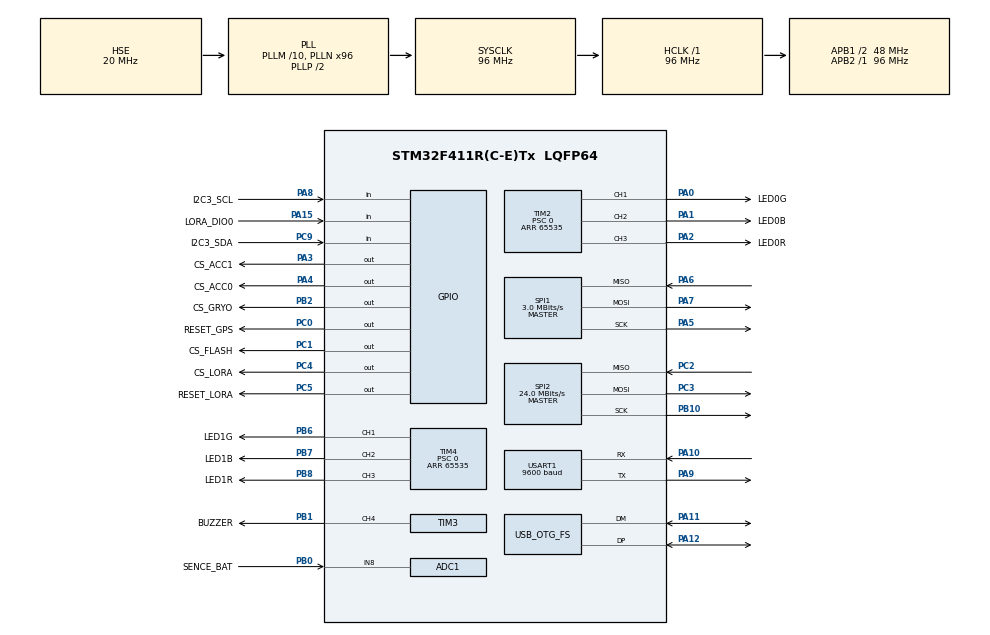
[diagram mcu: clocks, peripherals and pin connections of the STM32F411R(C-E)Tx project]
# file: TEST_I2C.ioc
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ADC1.Channel-0\#ChannelRegularConversion=ADC_CHANNEL_8
ADC1.NbrOfConversionFlag=1
ADC1.Rank-0\#ChannelRegularConversion=1
ADC1.SamplingTime-0\#ChannelRegularConversion=ADC_SAMPLETIME_3CYCLES
ADC1.master=1
Dma.ADC1.6.Direction=DMA_PERIPH_TO_MEMORY
Dma.ADC1.6.FIFOMode=DMA_FIFOMODE_DISABLE
Dma.ADC1.6.Instance=DMA2_Stream4
Dma.ADC1.6.MemDataAlignment=DMA_MDATAALIGN_HALFWORD
Dma.ADC1.6.MemInc=DMA_MINC_ENABLE
Dma.ADC1.6.Mode=DMA_NORMAL
Dma.ADC1.6.PeriphDataAlignment=DMA_PDATAALIGN_HALFWORD
Dma.ADC1.6.PeriphInc=DMA_PINC_DISABLE
Dma.ADC1.6.Priority=DMA_PRIORITY_LOW
Dma.Request0=SPI1_RX
Dma.Request1=SPI1_TX
Dma.Request2=SPI2_RX
Dma.Request3=SPI2_TX
Dma.Request4=USART1_RX
Dma.Request5=USART1_TX
Dma.Request6=ADC1
Dma.SPI1_RX.0.Direction=DMA_PERIPH_TO_MEMORY
Dma.SPI1_RX.0.FIFOMode=DMA_FIFOMODE_DISABLE
Dma.SPI1_RX.0.Instance=DMA2_Stream0
Dma.SPI1_RX.0.MemDataAlignment=DMA_MDATAALIGN_BYTE
Dma.SPI1_RX.0.MemInc=DMA_MINC_ENABLE
Dma.SPI1_RX.0.Mode=DMA_NORMAL
Dma.SPI1_RX.0.PeriphDataAlignment=DMA_PDATAALIGN_BYTE
Dma.SPI1_RX.0.PeriphInc=DMA_PINC_DISABLE
Dma.SPI1_RX.0.Priority=DMA_PRIORITY_LOW
Dma.SPI1_TX.1.Direction=DMA_MEMORY_TO_PERIPH
Dma.SPI1_TX.1.FIFOMode=DMA_FIFOMODE_DISABLE
Dma.SPI1_TX.1.Instance=DMA2_Stream2
Dma.SPI1_TX.1.MemDataAlignment=DMA_MDATAALIGN_BYTE
Dma.SPI1_TX.1.MemInc=DMA_MINC_ENABLE
Dma.SPI1_TX.1.Mode=DMA_NORMAL
Dma.SPI1_TX.1.PeriphDataAlignment=DMA_PDATAALIGN_BYTE
Dma.SPI1_TX.1.PeriphInc=DMA_PINC_DISABLE
Dma.SPI1_TX.1.Priority=DMA_PRIORITY_LOW
Dma.SPI2_RX.2.Direction=DMA_PERIPH_TO_MEMORY
Dma.SPI2_RX.2.FIFOMode=DMA_FIFOMODE_DISABLE
Dma.SPI2_RX.2.Instance=DMA1_Stream3
Dma.SPI2_RX.2.MemDataAlignment=DMA_MDATAALIGN_BYTE
Dma.SPI2_RX.2.MemInc=DMA_MINC_ENABLE
Dma.SPI2_RX.2.Mode=DMA_NORMAL
Dma.SPI2_RX.2.PeriphDataAlignment=DMA_PDATAALIGN_BYTE
Dma.SPI2_RX.2.PeriphInc=DMA_PINC_DISABLE
Dma.SPI2_RX.2.Priority=DMA_PRIORITY_LOW
Dma.SPI2_TX.3.Direction=DMA_MEMORY_TO_PERIPH
Dma.SPI2_TX.3.FIFOMode=DMA_FIFOMODE_DISABLE
Dma.SPI2_TX.3.Instance=DMA1_Stream4
Dma.SPI2_TX.3.MemDataAlignment=DMA_MDATAALIGN_BYTE
Dma.SPI2_TX.3.MemInc=DMA_MINC_ENABLE
Dma.SPI2_TX.3.Mode=DMA_NORMAL
Dma.SPI2_TX.3.PeriphDataAlignment=DMA_PDATAALIGN_BYTE
Dma.SPI2_TX.3.PeriphInc=DMA_PINC_DISABLE
Dma.SPI2_TX.3.Priority=DMA_PRIORITY_LOW
Dma.USART1_RX.4.Direction=DMA_PERIPH_TO_MEMORY
Dma.USART1_RX.4.FIFOMode=DMA_FIFOMODE_DISABLE
Dma.USART1_RX.4.Instance=DMA2_Stream5
Dma.USART1_RX.4.MemDataAlignment=DMA_MDATAALIGN_BYTE
Dma.USART1_RX.4.MemInc=DMA_MINC_ENABLE
Dma.USART1_RX.4.Mode=DMA_NORMAL
Dma.USART1_RX.4.PeriphDataAlignment=DMA_PDATAALIGN_BYTE
Dma.USART1_RX.4.PeriphInc=DMA_PINC_DISABLE
Dma.USART1_RX.4.Priority=DMA_PRIORITY_LOW
Dma.USART1_TX.5.Direction=DMA_MEMORY_TO_PERIPH
Dma.USART1_TX.5.FIFOMode=DMA_FIFOMODE_DISABLE
Dma.USART1_TX.5.Instance=DMA2_Stream7
Dma.USART1_TX.5.MemDataAlignment=DMA_MDATAALIGN_BYTE
Dma.USART1_TX.5.MemInc=DMA_MINC_ENABLE
Dma.USART1_TX.5.Mode=DMA_NORMAL
Dma.USART1_TX.5.PeriphDataAlignment=DMA_PDATAALIGN_BYTE
Dma.USART1_TX.5.PeriphInc=DMA_PINC_DISABLE
Dma.USART1_TX.5.Priority=DMA_PRIORITY_LOW
Mcu.Family=STM32F4
Mcu.Name=STM32F411R(C-E)Tx
Mcu.Package=LQFP64
NVIC.DMA1_Stream3_IRQn=true\:0\:0\:false\:false\:true\:false\:true\:true
NVIC.DMA1_Stream4_IRQn=true\:0\:0\:false\:false\:true\:false\:true\:true
NVIC.DMA2_Stream0_IRQn=true\:0\:0\:false\:false\:true\:false\:true\:true
NVIC.DMA2_Stream2_IRQn=true\:0\:0\:false\:false\:true\:false\:true\:true
NVIC.DMA2_Stream4_IRQn=true\:0\:0\:false\:false\:true\:false\:true\:true
NVIC.DMA2_Stream5_IRQn=true\:0\:0\:false\:false\:true\:false\:true\:true
NVIC.DMA2_Stream7_IRQn=true\:0\:0\:false\:false\:true\:false\:true\:true
NVIC.OTG_FS_IRQn=true\:0\:0\:false\:false\:true\:false\:true\:true
NVIC.PriorityGroup=NVIC_PRIORITYGROUP_4
PA0-WKUP.GPIO_Label=LED0G
PA0-WKUP.Signal=S_TIM2_CH1_ETR
PA1.GPIO_Label=LED0B
PA1.Signal=S_TIM2_CH2
PA10.Mode=Asynchronous
PA10.Signal=USART1_RX
PA11.Mode=Device_Only
PA11.Signal=USB_OTG_FS_DM
PA12.Mode=Device_Only
PA12.Signal=USB_OTG_FS_DP
PA13.Mode=Serial_Wire
PA13.Signal=SYS_JTMS-SWDIO
PA14.Mode=Serial_Wire
PA14.Signal=SYS_JTCK-SWCLK
PA15.GPIO_Label=LORA_DIO0
PA15.Signal=GPIO_Input
PA2.GPIO_Label=LED0R
PA2.Signal=S_TIM2_CH3
PA3.GPIO_Label=CS_ACC1
PA3.PinState=GPIO_PIN_SET
PA3.Signal=GPIO_Output
PA4.GPIO_Label=CS_ACC0
PA4.PinState=GPIO_PIN_SET
PA4.Signal=GPIO_Output
PA5.Mode=Full_Duplex_Master
PA5.Signal=SPI1_SCK
PA6.Mode=Full_Duplex_Master
PA6.Signal=SPI1_MISO
PA7.Mode=Full_Duplex_Master
PA7.Signal=SPI1_MOSI
PA8.GPIO_Label=I2C3_SCL
PA8.Signal=GPIO_Input
PA9.Mode=Asynchronous
PA9.Signal=USART1_TX
PB0.GPIO_Label=SENCE_BAT
PB0.Signal=ADCx_IN8
PB1.GPIO_Label=BUZZER
PB1.Signal=S_TIM3_CH4
PB10.Mode=Full_Duplex_Master
PB10.Signal=SPI2_SCK
PB2.GPIO_Label=CS_GRYO
PB2.PinState=GPIO_PIN_SET
PB2.Signal=GPIO_Output
PB6.GPIO_Label=LED1G
PB6.Signal=S_TIM4_CH1
PB7.GPIO_Label=LED1B
PB7.Signal=S_TIM4_CH2
PB8.GPIO_Label=LED1R
PB8.Signal=S_TIM4_CH3
PC0.GPIO_Label=RESET_GPS
PC0.PinState=GPIO_PIN_SET
PC0.Signal=GPIO_Output
PC1.GPIO_Label=CS_FLASH
PC1.PinState=GPIO_PIN_SET
PC1.Signal=GPIO_Output
PC14-OSC32_IN.Mode=LSE-External-Oscillator
PC14-OSC32_IN.Signal=RCC_OSC32_IN
PC15-OSC32_OUT.Mode=LSE-External-Oscillator
PC15-OSC32_OUT.Signal=RCC_OSC32_OUT
PC2.Mode=Full_Duplex_Master
PC2.Signal=SPI2_MISO
PC3.Mode=Full_Duplex_Master
PC3.Signal=SPI2_MOSI
PC4.GPIO_Label=CS_LORA
PC4.PinState=GPIO_PIN_SET
PC4.Signal=GPIO_Output
PC5.GPIO_Label=RESET_LORA
PC5.PinState=GPIO_PIN_SET
PC5.Signal=GPIO_Output
PC9.GPIO_Label=I2C3_SDA
PC9.Signal=GPIO_Input
PH0\ -\ OSC_IN.Mode=HSE-External-Oscillator
PH0\ -\ OSC_IN.Signal=RCC_OSC_IN
PH1\ -\ OSC_OUT.Mode=HSE-External-Oscillator
PH1\ -\ OSC_OUT.Signal=RCC_OSC_OUT
ProjectManager.HeapSize=0x200
ProjectManager.StackSize=0x400
ProjectManager.TargetToolchain=CMake
RCC.48MHZClocksFreq_Value=48000000
RCC.AHBFreq_Value=96000000
RCC.APB1CLKDivider=RCC_HCLK_DIV2
RCC.APB1Freq_Value=48000000
RCC.APB1TimFreq_Value=96000000
RCC.APB2Freq_Value=96000000
RCC.APB2TimFreq_Value=96000000
RCC.CortexFreq_Value=96000000
RCC.HCLKFreq_Value=96000000
RCC.HSE_VALUE=20000000
RCC.HSI_VALUE=16000000
RCC.PLLM=10
RCC.PLLN=96
RCC.SYSCLKFreq_VALUE=96000000
RCC.SYSCLKSource=RCC_SYSCLKSOURCE_PLLCLK
RCC.VCOOutputFreq_Value=192000000
SH.ADCx_IN8.0=ADC1_IN8,IN8
SH.S_TIM2_CH1_ETR.0=TIM2_CH1,PWM Generation1 CH1
SH.S_TIM2_CH2.0=TIM2_CH2,PWM Generation2 CH2
SH.S_TIM2_CH3.0=TIM2_CH3,PWM Generation3 CH3
SH.S_TIM3_CH4.0=TIM3_CH4,PWM Generation4 CH4
SH.S_TIM4_CH1.0=TIM4_CH1,PWM Generation1 CH1
SH.S_TIM4_CH2.0=TIM4_CH2,PWM Generation2 CH2
SH.S_TIM4_CH3.0=TIM4_CH3,PWM Generation3 CH3
SPI1.BaudRatePrescaler=SPI_BAUDRATEPRESCALER_32
SPI1.CalculateBaudRate=3.0 MBits/s
SPI1.Direction=SPI_DIRECTION_2LINES
SPI1.Mode=SPI_MODE_MASTER
SPI1.VirtualType=VM_MASTER
SPI2.CalculateBaudRate=24.0 MBits/s
SPI2.Direction=SPI_DIRECTION_2LINES
SPI2.Mode=SPI_MODE_MASTER
SPI2.VirtualType=VM_MASTER
TIM2.Channel-PWM\ Generation1\ CH1=TIM_CHANNEL_1
TIM2.Channel-PWM\ Generation2\ CH2=TIM_CHANNEL_2
TIM2.Channel-PWM\ Generation3\ CH3=TIM_CHANNEL_3
TIM2.Period=65535
TIM2.Prescaler=0
TIM3.Channel-PWM\ Generation4\ CH4=TIM_CHANNEL_4
TIM3.Period=65535
TIM3.Prescaler=0
TIM4.Channel-PWM\ Generation1\ CH1=TIM_CHANNEL_1
TIM4.Channel-PWM\ Generation2\ CH2=TIM_CHANNEL_2
TIM4.Channel-PWM\ Generation3\ CH3=TIM_CHANNEL_3
TIM4.Period=65535
TIM4.Prescaler=0
USART1.BaudRate=9600
USART1.VirtualMode=VM_ASYNC
USB_DEVICE.CLASS_NAME_FS=CDC
USB_DEVICE.VirtualMode=Cdc
USB_DEVICE.VirtualModeFS=Cdc_FS
USB_OTG_FS.VirtualMode=Device_Only
VP_TIM2_VS_ClockSourceINT.Mode=Internal
VP_TIM3_VS_ClockSourceINT.Mode=Internal
VP_TIM4_VS_ClockSourceINT.Mode=Internal
VP_USB_DEVICE_VS_USB_DEVICE_CDC_FS.Mode=CDC_FS
board=custom

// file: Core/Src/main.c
/* USER CODE BEGIN Header */
/**
  ******************************************************************************
  * @file           : main.c
  * @brief          : Main program body
  ******************************************************************************
  * @attention
  *
  * Copyright (c) 2025 STMicroelectronics.
  * All rights reserved.
  *
  * This software is licensed under terms that can be found in the LICENSE file
  * in the root directory of this software component.
  * If no LICENSE file comes with this software, it is provided AS-IS.
  *
  ******************************************************************************
  */
/* USER CODE END Header */
#include "main.h"
#include "adc.h"
#include "dma.h"
#include "spi.h"
#include "tim.h"
#include "usart.h"
#include "usb_device.h"
#include "gpio.h"
#include "usbd_cdc_if.h"

void SystemClock_Config(void);

int main(void)
{

  /* MCU Configuration--------------------------------------------------------*/

  /* Reset of all peripherals, Initializes the Flash interface and the Systick. */
  HAL_Init();

  /* Configure the system clock */
  SystemClock_Config();

  /* Initialize all configured peripherals */
  MX_GPIO_Init();
  MX_DMA_Init();
  MX_SPI2_Init();
  MX_TIM2_Init();
  MX_TIM4_Init();
  MX_USART1_UART_Init();
  MX_ADC1_Init();
  MX_SPI1_Init();
  MX_TIM3_Init();
  MX_USB_DEVICE_Init();
  /* USER CODE BEGIN 2 */

  uint8_t sda, scl;

  char usb_buffer[64];

  /* USER CODE END 2 */

  /* Infinite loop */
  /* USER CODE BEGIN WHILE */
  while (1)
  {

    HAL_GPIO_ReadPin(I2C3_SDA_GPIO_Port, I2C3_SDA_Pin) ? (sda = 1) : (sda = 0);
    HAL_GPIO_ReadPin(I2C3_SCL_GPIO_Port, I2C3_SCL_Pin) ? (scl = 1) : (scl = 0);

    sprintf(usb_buffer, "SDA: %d, SCL: %d\r\n", sda, scl);
    CDC_Transmit_FS((uint8_t *)usb_buffer, strlen(usb_buffer));

  HAL_Delay(1000); // Transmit every second
    /* USER CODE END WHILE */

  }
}

void SystemClock_Config(void)
{
  RCC_OscInitTypeDef RCC_OscInitStruct = {0};
  RCC_ClkInitTypeDef RCC_ClkInitStruct = {0};

  /** Configure the main internal regulator output voltage
  */
  __HAL_RCC_PWR_CLK_ENABLE();
  __HAL_PWR_VOLTAGESCALING_CONFIG(PWR_REGULATOR_VOLTAGE_SCALE1);

  /** Initializes the RCC Oscillators according to the specified parameters
  * in the RCC_OscInitTypeDef structure.
  */
  RCC_OscInitStruct.OscillatorType = RCC_OSCILLATORTYPE_HSE;
  RCC_OscInitStruct.HSEState = RCC_HSE_ON;
  RCC_OscInitStruct.PLL.PLLState = RCC_PLL_ON;
  RCC_OscInitStruct.PLL.PLLSource = RCC_PLLSOURCE_HSE;
  RCC_OscInitStruct.PLL.PLLM = 10;
  RCC_OscInitStruct.PLL.PLLN = 96;
  RCC_OscInitStruct.PLL.PLLP = RCC_PLLP_DIV2;
  RCC_OscInitStruct.PLL.PLLQ = 4;
  if (HAL_RCC_OscConfig(&RCC_OscInitStruct) != HAL_OK)
  {
    Error_Handler();
  }

  /** Initializes the CPU, AHB and APB buses clocks
  */
  RCC_ClkInitStruct.ClockType = RCC_CLOCKTYPE_HCLK|RCC_CLOCKTYPE_SYSCLK
                              |RCC_CLOCKTYPE_PCLK1|RCC_CLOCKTYPE_PCLK2;
  RCC_ClkInitStruct.SYSCLKSource = RCC_SYSCLKSOURCE_PLLCLK;
  RCC_ClkInitStruct.AHBCLKDivider = RCC_SYSCLK_DIV1;
  RCC_ClkInitStruct.APB1CLKDivider = RCC_HCLK_DIV2;
  RCC_ClkInitStruct.APB2CLKDivider = RCC_HCLK_DIV1;

  if (HAL_RCC_ClockConfig(&RCC_ClkInitStruct, FLASH_LATENCY_3) != HAL_OK)
  {
    Error_Handler();
  }
}

void Error_Handler(void)
{
  __disable_irq();
  while (1)
  {
  }
}
